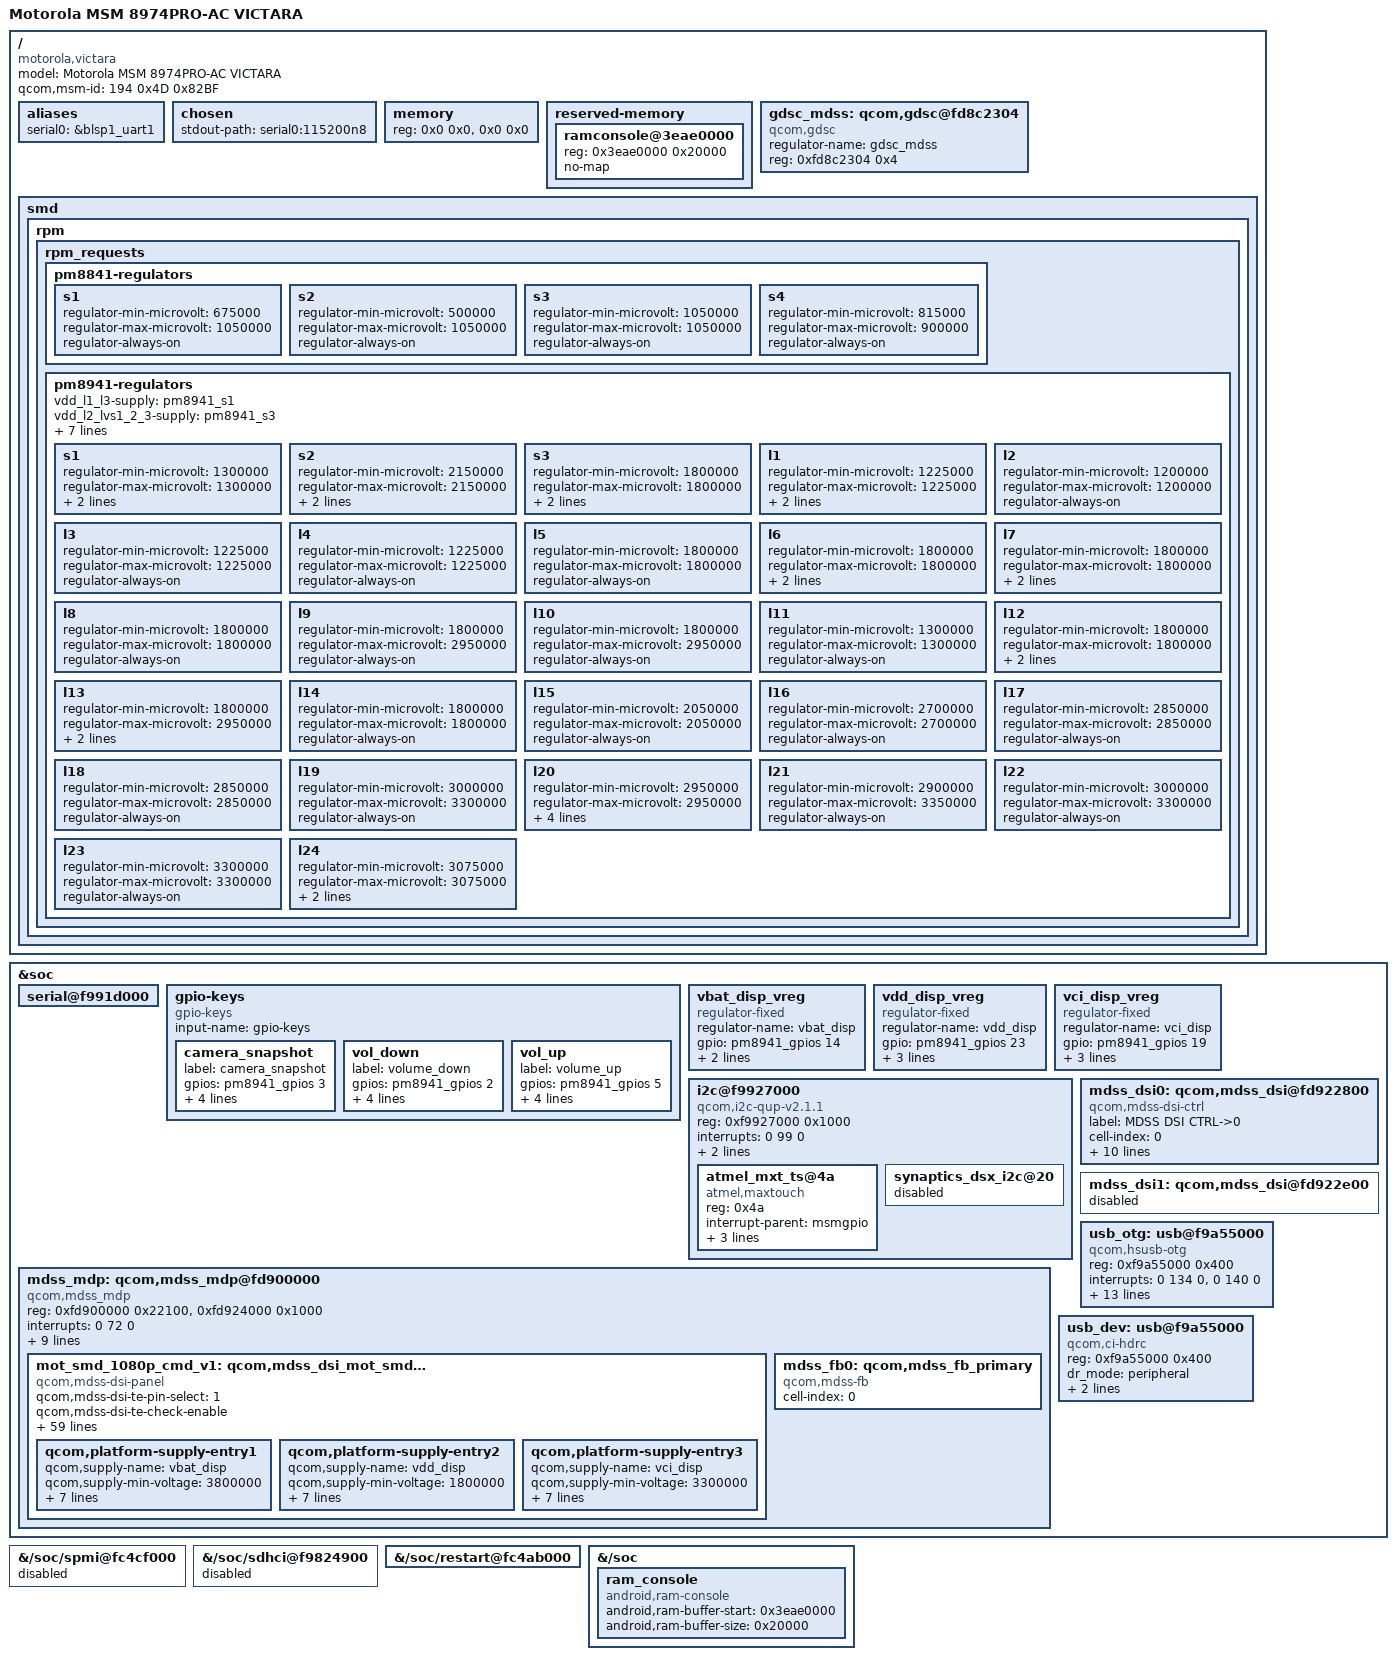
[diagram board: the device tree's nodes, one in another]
/*
 * victara board device tree. regulator and serial blocks based on
 * qcom-msm8974-lge-nexus5-hammerhead.dts by Bhushan Shah. mdss, panel,
 * touch, keys and emmc settings from the moto 3.4 stock dts.
 */

#include "qcom-msm8974.dtsi"
#include "qcom-pm8841.dtsi"
#include "qcom-pm8941.dtsi"
#include <dt-bindings/gpio/gpio.h>
#include <dt-bindings/clock/qcom,mmcc-msm8974.h>

/ {
	model = "Motorola MSM 8974PRO-AC VICTARA";
	compatible = "motorola,victara", "qcom,msm8974";
	qcom,msm-id = <194 0x4D 0x82BF>;

	aliases {
		serial0 = &blsp1_uart1;
	};

	chosen {
		stdout-path = "serial0:115200n8";
	};

	memory {
		device_type = "memory";
		reg = <0x0 0x0>, <0x0 0x0>;
	};

	reserved-memory {
		#address-cells = <1>;
		#size-cells = <1>;
		ranges;

		/* keep this out of the page allocator from the start.
		 * a late memblock reserve races with allocations. */
		ramconsole@3eae0000 {
			reg = <0x3eae0000 0x20000>;
			no-map;
		};
	};

	gdsc_mdss: qcom,gdsc@fd8c2304 {
		compatible = "qcom,gdsc";
		regulator-name = "gdsc_mdss";
		reg = <0xfd8c2304 0x4>;
	};

	smd {
		rpm {
			rpm_requests {
				pm8841-regulators {
					s1 {
						regulator-min-microvolt = <675000>;
						regulator-max-microvolt = <1050000>;
						regulator-always-on;
					};

					s2 {
						regulator-min-microvolt = <500000>;
						regulator-max-microvolt = <1050000>;
						regulator-always-on;
					};

					s3 {
						regulator-min-microvolt = <1050000>;
						regulator-max-microvolt = <1050000>;
						regulator-always-on;
					};

					s4 {
						regulator-min-microvolt = <815000>;
						regulator-max-microvolt = <900000>;
						regulator-always-on;
					};
				};

				pm8941-regulators {
					vdd_l1_l3-supply = <&pm8941_s1>;
					vdd_l2_lvs1_2_3-supply = <&pm8941_s3>;
					vdd_l4_l11-supply = <&pm8941_s1>;
					vdd_l5_l7-supply = <&pm8941_s2>;
					vdd_l6_l12_l14_l15-supply = <&pm8941_s2>;
					vdd_l8_l16_l18_l19-supply = <&vreg_vph_pwr>;
					vdd_l9_l10_l17_l22-supply = <&vreg_boost>;
					vdd_l13_l20_l23_l24-supply = <&vreg_boost>;
					vdd_l21-supply = <&vreg_boost>;

					s1 {
						regulator-min-microvolt = <1300000>;
						regulator-max-microvolt = <1300000>;

						regulator-always-on;
						regulator-boot-on;
					};

					s2 {
						regulator-min-microvolt = <2150000>;
						regulator-max-microvolt = <2150000>;
						regulator-always-on;

						regulator-boot-on;
					};

					s3 {
						regulator-min-microvolt = <1800000>;
						regulator-max-microvolt = <1800000>;

						regulator-always-on;
						regulator-boot-on;
					};

					l1 {
						regulator-min-microvolt = <1225000>;
						regulator-max-microvolt = <1225000>;

						regulator-always-on;
						regulator-boot-on;
					};

					l2 {
						regulator-min-microvolt = <1200000>;
						regulator-max-microvolt = <1200000>;
						regulator-always-on;
					};

					l3 {
						regulator-min-microvolt = <1225000>;
						regulator-max-microvolt = <1225000>;
						regulator-always-on;
					};

					l4 {
						regulator-min-microvolt = <1225000>;
						regulator-max-microvolt = <1225000>;
						regulator-always-on;
					};

					l5 {
						regulator-min-microvolt = <1800000>;
						regulator-max-microvolt = <1800000>;
						regulator-always-on;
					};

					l6 {
						regulator-min-microvolt = <1800000>;
						regulator-max-microvolt = <1800000>;
						regulator-always-on;

						regulator-boot-on;
					};

					l7 {
						regulator-min-microvolt = <1800000>;
						regulator-max-microvolt = <1800000>;
						regulator-always-on;

						regulator-boot-on;
					};

					l8 {
						regulator-min-microvolt = <1800000>;
						regulator-max-microvolt = <1800000>;
						regulator-always-on;
					};

					l9 {
						regulator-min-microvolt = <1800000>;
						regulator-max-microvolt = <2950000>;
						regulator-always-on;
					};

					l10 {
						regulator-min-microvolt = <1800000>;
						regulator-max-microvolt = <2950000>;
						regulator-always-on;
					};

					l11 {
						regulator-min-microvolt = <1300000>;
						regulator-max-microvolt = <1300000>;
						regulator-always-on;
					};

					l12 {
						regulator-min-microvolt = <1800000>;
						regulator-max-microvolt = <1800000>;

						regulator-always-on;
						regulator-boot-on;
					};

					l13 {
						regulator-min-microvolt = <1800000>;
						regulator-max-microvolt = <2950000>;

						regulator-always-on;
						regulator-boot-on;
					};

					l14 {
						regulator-min-microvolt = <1800000>;
						regulator-max-microvolt = <1800000>;
						regulator-always-on;
					};

					l15 {
						regulator-min-microvolt = <2050000>;
						regulator-max-microvolt = <2050000>;
						regulator-always-on;
					};

					l16 {
						regulator-min-microvolt = <2700000>;
						regulator-max-microvolt = <2700000>;
						regulator-always-on;
					};

					l17 {
						regulator-min-microvolt = <2850000>;
						regulator-max-microvolt = <2850000>;

						regulator-always-on;
					};

					l18 {
						regulator-min-microvolt = <2850000>;
						regulator-max-microvolt = <2850000>;
						regulator-always-on;
					};

					l19 {
						regulator-min-microvolt = <3000000>;
						regulator-max-microvolt = <3300000>;
						regulator-always-on;
					};

					l20 {
						regulator-min-microvolt = <2950000>;
						regulator-max-microvolt = <2950000>;
						regulator-always-on;

						regulator-boot-on;
						regulator-system-load = <200000>;
						regulator-allow-set-load;
					};

					l21 {
						regulator-min-microvolt = <2900000>;
						regulator-max-microvolt = <3350000>;
						regulator-always-on;
					};

					l22 {
						regulator-min-microvolt = <3000000>;
						regulator-max-microvolt = <3300000>;

						regulator-always-on;
					};

					l23 {
						regulator-min-microvolt = <3300000>;
						regulator-max-microvolt = <3300000>;

						regulator-always-on;
					};

					l24 {
						regulator-min-microvolt = <3075000>;
						regulator-max-microvolt = <3075000>;
						regulator-always-on;

						regulator-boot-on;
					};
				};
			};
		};
	};
};

&soc {
	serial@f991d000 {
		status = "ok";
	};

	gpio-keys {
		compatible = "gpio-keys";
		input-name = "gpio-keys";

		camera_snapshot {
			label = "camera_snapshot";
			gpios = <&pm8941_gpios 3 GPIO_ACTIVE_HIGH>;
			linux,input-type = <1>;
			linux,code = <0x2fe>;
			gpio-key,wakeup;
			debounce-interval = <15>;
		};

		vol_down {
			label = "volume_down";
			gpios = <&pm8941_gpios 2 GPIO_ACTIVE_HIGH>;
			linux,input-type = <1>;
			linux,code = <114>;
			gpio-key,wakeup;
			debounce-interval = <15>;
		};

		vol_up {
			label = "volume_up";
			gpios = <&pm8941_gpios 5 GPIO_ACTIVE_HIGH>;
			linux,input-type = <1>;
			linux,code = <115>;
			gpio-key,wakeup;
			debounce-interval = <15>;
		};
	};

	vbat_disp_vreg: vbat_disp_vreg {
		compatible = "regulator-fixed";
		regulator-name = "vbat_disp";
		gpio = <&pm8941_gpios 14 0x0>;
		startup-delay-us = <300>;
		enable-active-high;
	};

	vdd_disp_vreg: vdd_disp_vreg {
		compatible = "regulator-fixed";
		regulator-name = "vdd_disp";
		gpio = <&pm8941_gpios 23 0x0>;
		parent-supply = <&pm8941_s3>;
		startup-delay-us = <300>;
		enable-active-high;
	};

	vci_disp_vreg: vci_disp_vreg {
		compatible = "regulator-fixed";
		regulator-name = "vci_disp";
		gpio = <&pm8941_gpios 19 0>;
		parent-supply = <&pm8941_l23>;
		startup-delay-us = <300>;
		enable-active-high;
	};

	i2c@f9927000 {
		status = "ok";
		compatible = "qcom,i2c-qup-v2.1.1";
		reg = <0xf9927000 0x1000>;
		interrupts = <0 99 0>;
		clocks = <&gcc GCC_BLSP1_QUP4_I2C_APPS_CLK>,
			 <&gcc GCC_BLSP1_AHB_CLK>;
		clock-names = "core", "iface";
		#address-cells = <1>;
		#size-cells = <0>;

		atmel_mxt_ts@4a {
			compatible = "atmel,maxtouch";
			reg = <0x4a>;
			interrupt-parent = <&msmgpio>;
			interrupts = <62 0>;
			touch_vdd-supply = <&pm8941_s3>;
			touch_avdd-supply = <&pm8941_l23>;
		};

		synaptics_dsx_i2c@20 {
			status = "disabled";
		};
	};

	mdss_mdp: qcom,mdss_mdp@fd900000 {
		compatible = "qcom,mdss_mdp";
		reg = <0xfd900000 0x22100>,
			<0xfd924000 0x1000>;
		reg-names = "mdp_phys", "vbif_phys";
		interrupts = <0 72 0>;
		vdd-supply = <&gdsc_mdss>;
		clocks = <&mmcc MDSS_AHB_CLK>,
			 <&mmcc MDSS_AXI_CLK>,
			 <&mmcc MDSS_MDP_CLK>,
			 <&mmcc MDSS_VSYNC_CLK>;
		clock-names = "iface_clk", "bus_clk",
			      "core_clk", "vsync_clk";

		qcom,mdss-pipe-vig-off = <0x00001200 0x00001600
					       0x00001A00>;
		qcom,mdss-pipe-rgb-off = <0x00001E00 0x00002200
					       0x00002600>;
		qcom,mdss-pipe-dma-off = <0x00002A00 0x00002E00>;
		qcom,mdss-smp-data = <22 4096>;

		mot_smd_1080p_cmd_v1: qcom,mdss_dsi_mot_smd_1080p_cmd_v1 {
			compatible = "qcom,mdss-dsi-panel";

			qcom,mdss-dsi-te-pin-select = <1>;
			qcom,mdss-dsi-te-check-enable;
			qcom,mdss-dsi-te-using-te-pin;
			qcom,mdss-dsi-te-dcs-command = <1>;

			qcom,mdss-dsi-hs-cmds-post-init;

			qcom,mdss-dsi-panel-name = "mipi_mot_cmd_smd_1080_v1";
			qcom,mdss-dsi-panel-controller = <&mdss_dsi0>;
			qcom,mdss-dsi-panel-type = "dsi_cmd_mode";
			qcom,mdss-dsi-panel-destination = "display_1";
			qcom,mdss-dsi-panel-framerate = <60>;
			qcom,mdss-dsi-panel-col-align = <8>;
			qcom,mdss-dsi-virtual-channel-id = <0>;
			qcom,mdss-dsi-stream = <0>;
			qcom,mdss-dsi-panel-width = <1080>;
			qcom,mdss-dsi-panel-height = <1920>;
			qcom,mdss-pan-physical-width-dimension = <65>;
			qcom,mdss-pan-physical-height-dimension = <115>;

			qcom,panel-roi-alignment = <8 8 0 0 0 0>;

			qcom,mdss-dsi-h-front-porch = <144>;
			qcom,mdss-dsi-h-back-porch = <32>;
			qcom,mdss-dsi-h-pulse-width = <12>;
			qcom,mdss-dsi-h-sync-skew = <0>;
			qcom,mdss-dsi-v-back-porch = <3>;
			qcom,mdss-dsi-v-front-porch = <9>;
			qcom,mdss-dsi-v-pulse-width = <4>;
			qcom,mdss-dsi-h-left-border = <0>;
			qcom,mdss-dsi-h-right-border = <0>;
			qcom,mdss-dsi-v-top-border = <0>;
			qcom,mdss-dsi-v-bottom-border = <0>;
			qcom,mdss-dsi-bpp = <24>;
			qcom,mdss-dsi-underflow-color = <0xff>;
			qcom,mdss-dsi-border-color = <0>;

			qcom,mdss-dsi-on-command = [
					05 01 00 00 78 00 01 11
					29 01 00 00 00 00 03 f0 5a 5a
					29 01 00 00 00 00 03 fc 5a 5a
					15 01 00 00 00 00 02 b0 04
					15 01 00 00 00 00 02 fd 0c
					15 01 00 00 00 00 02 b0 02
					15 01 00 00 00 00 02 b1 16
					15 01 00 00 01 00 02 35 00
					15 01 00 00 01 00 02 51 00
					15 01 00 00 01 00 02 55 03
					15 01 00 00 01 00 02 53 20
					39 01 00 00 00 00 05 2a 00 00 04 37
					39 01 00 00 00 00 05 2b 00 00 07 7f
					39 01 00 00 00 00 05 30 00 00 07 7f
					05 01 00 00 00 00 01 13
					05 01 00 00 00 00 01 29];

			qcom,mdss-dsi-off-command = [
					05 01 00 00 0a 00 01 28
					05 01 00 00 78 00 01 10];

			qcom,mdss-dsi-on-command-state = "dsi_lp_mode";
			qcom,mdss-dsi-off-command-state = "dsi_hs_mode";
			qcom,mdss-dsi-h-sync-pulse = <0>;
			qcom,mdss-dsi-traffic-mode = "non_burst_sync_event";
			qcom,mdss-dsi-bllp-eof-power-mode;
			qcom,mdss-dsi-bllp-power-mode;
			qcom,mdss-dsi-lane-0-state;
			qcom,mdss-dsi-lane-1-state;
			qcom,mdss-dsi-lane-2-state;
			qcom,mdss-dsi-lane-3-state;
			qcom,mdss-dsi-tx-eot-append;
			qcom,mdss-dsi-panel-clockrate = <0>;
			qcom,mdss-dsi-panel-timings = [b0 23 1b 00 94 93 1e 25 15 03 04 00];
			qcom,mdss-dsi-t-clk-post = <0x04>;
			qcom,mdss-dsi-t-clk-pre = <0x1b>;
			qcom,mdss-dsi-bl-min-level = <1>;
			qcom,mdss-dsi-bl-max-level = <255>;
			qcom,mdss-dsi-dma-trigger = "trigger_sw";
			qcom,mdss-dsi-mdp-trigger = "none";
			qcom,mdss-dsi-bl-pmic-control-type = "bl_ctrl_dcs";

			qcom,mdss-dsi-reset-sequence = <1 20>, <0 2>, <1 20>;

			qcom,platform-supply-entry1 {
				qcom,supply-name = "vbat_disp";
				qcom,supply-min-voltage = <3800000>;
				qcom,supply-max-voltage = <3800000>;
				qcom,supply-enable-load = <300000>;
				qcom,supply-disable-load = <100>;
				qcom,supply-pre-on-sleep = <0>;
				qcom,supply-post-on-sleep = <0>;
				qcom,supply-pre-off-sleep = <0>;
				qcom,supply-post-off-sleep = <0>;
			};
			qcom,platform-supply-entry2 {
				qcom,supply-name = "vdd_disp";
				qcom,supply-min-voltage = <1800000>;
				qcom,supply-max-voltage = <1800000>;
				qcom,supply-enable-load = <300000>;
				qcom,supply-disable-load = <100>;
				qcom,supply-pre-on-sleep = <0>;
				qcom,supply-post-on-sleep = <0>;
				qcom,supply-pre-off-sleep = <0>;
				qcom,supply-post-off-sleep = <0>;
			};
			qcom,platform-supply-entry3 {
				qcom,supply-name = "vci_disp";
				qcom,supply-min-voltage = <3300000>;
				qcom,supply-max-voltage = <3300000>;
				qcom,supply-enable-load = <300000>;
				qcom,supply-disable-load = <100>;
				qcom,supply-pre-on-sleep = <0>;
				qcom,supply-post-on-sleep = <21>;
				qcom,supply-pre-off-sleep = <0>;
				qcom,supply-post-off-sleep = <0>;
			};
		};

		mdss_fb0: qcom,mdss_fb_primary {
			cell-index = <0>;
			compatible = "qcom,mdss-fb";
		};
	};

	mdss_dsi0: qcom,mdss_dsi@fd922800 {
		compatible = "qcom,mdss-dsi-ctrl";
		label = "MDSS DSI CTRL->0";
		cell-index = <0>;
		reg = <0xfd922800 0x200>,
			<0xfd922a00 0x200>;
		reg-names = "dsi_ctrl", "dsi_phy";
		vdd-supply = <&pm8941_l22>;
		vddio-supply = <&pm8941_l12>;
		vdda-supply = <&pm8941_l2>;
		clocks = <&mmcc MDSS_AHB_CLK>,
			 <&mmcc MDSS_AXI_CLK>,
			 <&mmcc MDSS_MDP_CLK>;
		clock-names = "iface_clk", "bus_clk",
			      "mdp_core_clk";
		qcom,mdss-mdp = <&mdss_mdp>;
		qcom,dsi-pref-prim-pan = <&mot_smd_1080p_cmd_v1>;
		qcom,mdss-fb-map = <&mdss_fb0>;
		qcom,platform-reset-gpio = <&pm8941_gpios 12 0>;
	};

	mdss_dsi1: qcom,mdss_dsi@fd922e00 {
		status = "disabled";
	};

	usb_otg: usb@f9a55000 {
		compatible = "qcom,hsusb-otg";
		reg = <0xf9a55000 0x400>;
		interrupts = <0 134 0>, <0 140 0>;
		interrupt-names = "core_irq", "async_irq";
		clocks = <&gcc GCC_USB_HS_SYSTEM_CLK>,
			 <&gcc GCC_USB_HS_AHB_CLK>,
			 <&xo>;
		clock-names = "core_clk", "iface_clk", "xo";
		HSUSB_VDDCX-supply = <&pm8841_s2>;
		HSUSB_1p8-supply = <&pm8941_l6>;
		HSUSB_3p3-supply = <&pm8941_l24>;
		qcom,vdd-voltage-level = <1 5 7>;
		qcom,hsusb-otg-phy-type = <2>;
		qcom,hsusb-otg-phy-init-seq = <0x63 0x81 0xffffffff>;
		qcom,hsusb-otg-mode = <1>;
		qcom,hsusb-otg-otg-control = <1>;
		qcom,hsusb-otg-disable-reset;
		dr_mode = "peripheral";
	};

	usb_dev: usb@f9a55000 {
		compatible = "qcom,ci-hdrc";
		reg = <0xf9a55000 0x400>;
		dr_mode = "peripheral";
		interrupts = <0 134 0>;
		usb-phy = <&usb_otg>;
	};
};

&{/soc/spmi@fc4cf000} {
	status = "disabled";
};

/* sdcc1, emmc */
&{/soc/sdhci@f9824900} {
	status = "disabled";
};

&{/soc/restart@fc4ab000} {
	reg-names = "pshold-base";
};

&{/soc} {
	ram_console {
		compatible = "android,ram-console";
		status = "ok";

		android,ram-buffer-start = <0x3eae0000>;
		android,ram-buffer-size = <0x20000>;
	};
};
